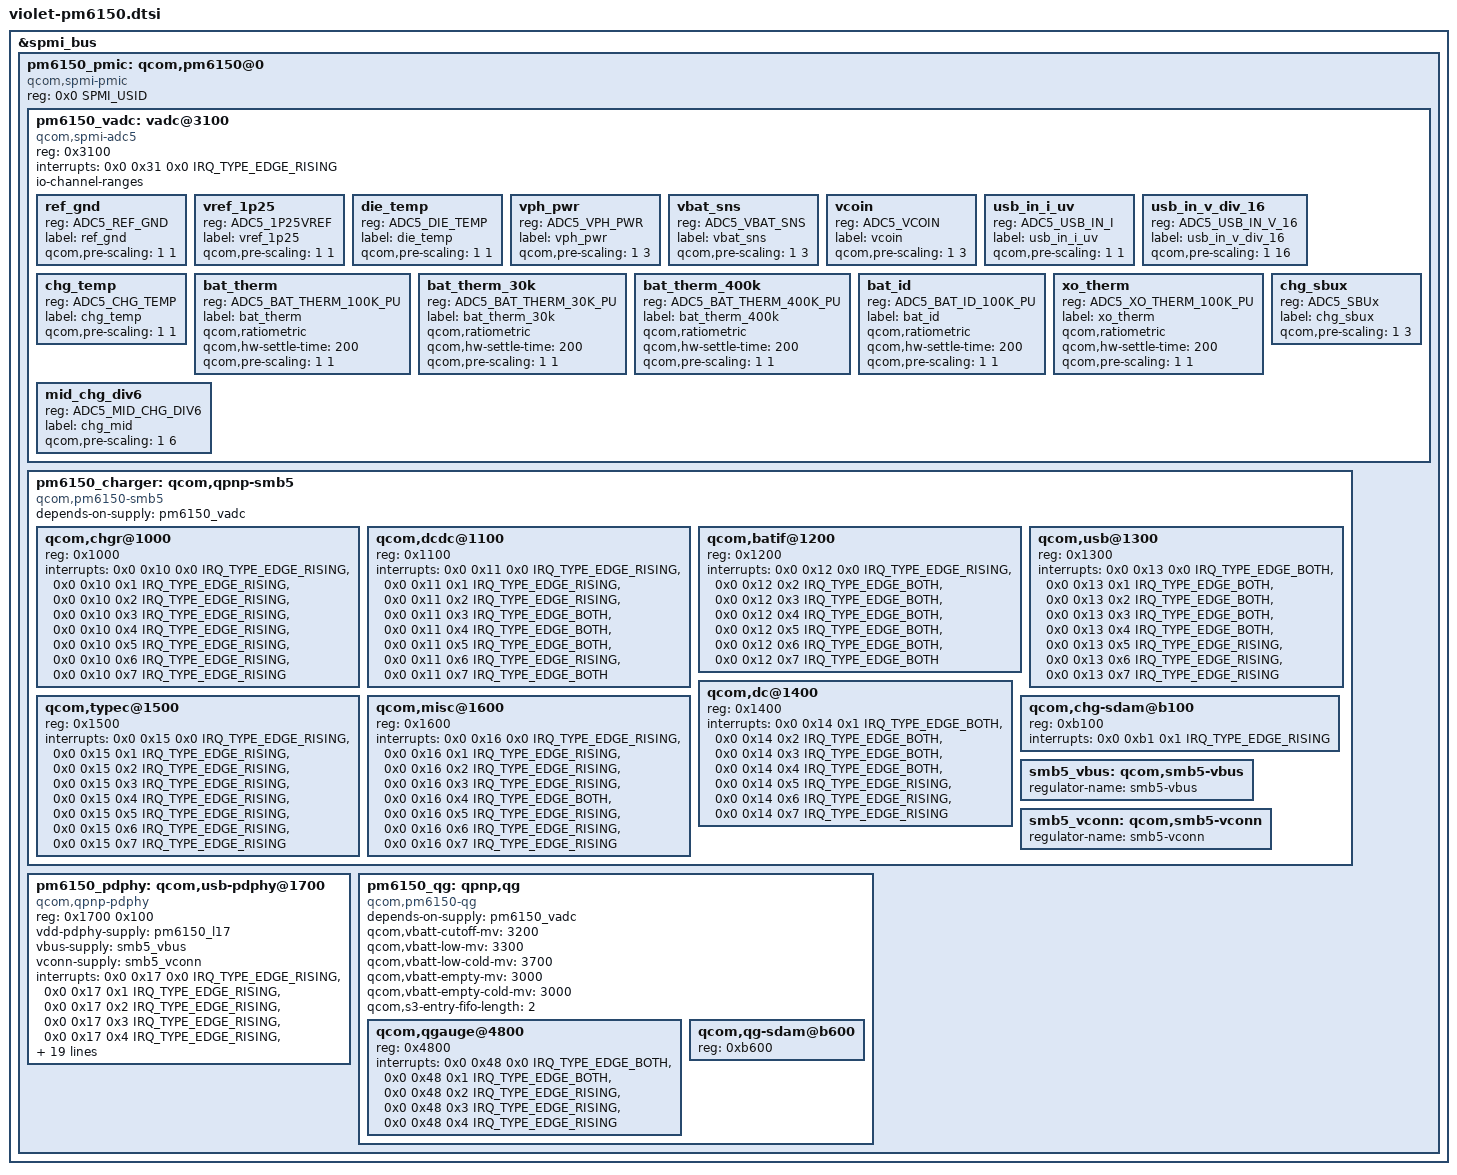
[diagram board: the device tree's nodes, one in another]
// SPDX-License-Identifier: GPL-2.0-only
/*
 * DEBUG (bring-up): pm6150 (SID 0) for the 6.1 charger/gauge drivers. Generated
 * from the 4.14 pm6150.dtsi with the 6.1 binding (single-cell reg, IIO
 * channels, pm6150-smb5 / pm6150-qg compatibles).
 */
#include <dt-bindings/spmi/spmi.h>
#include <dt-bindings/interrupt-controller/irq.h>
#include <dt-bindings/iio/qcom,spmi-vadc.h>
#include <dt-bindings/iio/qti_power_supply_iio.h>

&spmi_bus {
	pm6150_pmic: qcom,pm6150@0 {
		compatible = "qcom,spmi-pmic";
		reg = <0x0 SPMI_USID>;
		#address-cells = <1>;
		#size-cells = <0>;

		pm6150_vadc: vadc@3100 {
			compatible = "qcom,spmi-adc5";
			reg = <0x3100>;
			#address-cells = <1>;
			#size-cells = <0>;
			interrupts = <0x0 0x31 0x0 IRQ_TYPE_EDGE_RISING>;
			interrupt-names = "eoc-int-en-set";
			#io-channel-cells = <1>;
			io-channel-ranges;

			/* Channel nodes */
			ref_gnd {
				reg = <ADC5_REF_GND>;
				label = "ref_gnd";
				qcom,pre-scaling = <1 1>;
			};

			vref_1p25 {
				reg = <ADC5_1P25VREF>;
				label = "vref_1p25";
				qcom,pre-scaling = <1 1>;
			};

			die_temp {
				reg = <ADC5_DIE_TEMP>;
				label = "die_temp";
				qcom,pre-scaling = <1 1>;
			};

			vph_pwr {
				reg = <ADC5_VPH_PWR>;
				label = "vph_pwr";
				qcom,pre-scaling = <1 3>;
			};

			vbat_sns {
				reg = <ADC5_VBAT_SNS>;
				label = "vbat_sns";
				qcom,pre-scaling = <1 3>;
			};

			vcoin {
				reg = <ADC5_VCOIN>;
				label = "vcoin";
				qcom,pre-scaling = <1 3>;
			};

			usb_in_i_uv {
				reg = <ADC5_USB_IN_I>;
				label = "usb_in_i_uv";
				qcom,pre-scaling = <1 1>;
			};

			usb_in_v_div_16 {
				reg = <ADC5_USB_IN_V_16>;
				label = "usb_in_v_div_16";
				qcom,pre-scaling = <1 16>;
			};

			chg_temp {
				reg = <ADC5_CHG_TEMP>;
				label = "chg_temp";
				qcom,pre-scaling = <1 1>;
			};

			bat_therm {
				reg = <ADC5_BAT_THERM_100K_PU>;
				label = "bat_therm";
				qcom,ratiometric;
				qcom,hw-settle-time = <200>;
				qcom,pre-scaling = <1 1>;
			};

			bat_therm_30k {
				reg = <ADC5_BAT_THERM_30K_PU>;
				label = "bat_therm_30k";
				qcom,ratiometric;
				qcom,hw-settle-time = <200>;
				qcom,pre-scaling = <1 1>;
			};

			bat_therm_400k {
				reg = <ADC5_BAT_THERM_400K_PU>;
				label = "bat_therm_400k";
				qcom,ratiometric;
				qcom,hw-settle-time = <200>;
				qcom,pre-scaling = <1 1>;
			};

			bat_id {
				reg = <ADC5_BAT_ID_100K_PU>;
				label = "bat_id";
				qcom,ratiometric;
				qcom,hw-settle-time = <200>;
				qcom,pre-scaling = <1 1>;
			};

			xo_therm {
				reg = <ADC5_XO_THERM_100K_PU>;
				label = "xo_therm";
				qcom,ratiometric;
				qcom,hw-settle-time = <200>;
				qcom,pre-scaling = <1 1>;
			};

			chg_sbux {
				reg = <ADC5_SBUx>;
				label = "chg_sbux";
				qcom,pre-scaling = <1 3>;
			};

			mid_chg_div6 {
				reg = <ADC5_MID_CHG_DIV6>;
				label = "chg_mid";
				qcom,pre-scaling = <1 6>;
			};



		};

		pm6150_charger: qcom,qpnp-smb5 {
			compatible = "qcom,pm6150-smb5";
			depends-on-supply = <&pm6150_vadc>;
			#address-cells = <1>;
			#size-cells = <0>;
			#cooling-cells = <2>;


			qcom,chgr@1000 {
				reg = <0x1000>;
				interrupts =
					<0x0 0x10 0x0 IRQ_TYPE_EDGE_RISING>,
					<0x0 0x10 0x1 IRQ_TYPE_EDGE_RISING>,
					<0x0 0x10 0x2 IRQ_TYPE_EDGE_RISING>,
					<0x0 0x10 0x3 IRQ_TYPE_EDGE_RISING>,
					<0x0 0x10 0x4 IRQ_TYPE_EDGE_RISING>,
					<0x0 0x10 0x5 IRQ_TYPE_EDGE_RISING>,
					<0x0 0x10 0x6 IRQ_TYPE_EDGE_RISING>,
					<0x0 0x10 0x7 IRQ_TYPE_EDGE_RISING>;

				interrupt-names = "chgr-error",
						  "chg-state-change",
						  "step-chg-state-change",
						  "step-chg-soc-update-fail",
						  "step-chg-soc-update-req",
						  "fg-fvcal-qualified",
						  "vph-alarm",
						  "vph-drop-prechg";
			};

			qcom,dcdc@1100 {
				reg = <0x1100>;
				interrupts =
					<0x0 0x11 0x0 IRQ_TYPE_EDGE_RISING>,
					<0x0 0x11 0x1 IRQ_TYPE_EDGE_RISING>,
					<0x0 0x11 0x2 IRQ_TYPE_EDGE_RISING>,
					<0x0 0x11 0x3 IRQ_TYPE_EDGE_BOTH>,
					<0x0 0x11 0x4 IRQ_TYPE_EDGE_BOTH>,
					<0x0 0x11 0x5 IRQ_TYPE_EDGE_BOTH>,
					<0x0 0x11 0x6 IRQ_TYPE_EDGE_RISING>,
					<0x0 0x11 0x7 IRQ_TYPE_EDGE_BOTH>;

				interrupt-names = "otg-fail",
						  "otg-oc-disable-sw",
						  "otg-oc-hiccup",
						  "bsm-active",
						  "high-duty-cycle",
						  "input-current-limiting",
						  "concurrent-mode-disable",
						  "switcher-power-ok";
			};

			qcom,batif@1200 {
				reg = <0x1200>;
				interrupts =
					<0x0 0x12 0x0 IRQ_TYPE_EDGE_RISING>,
					<0x0 0x12 0x2 IRQ_TYPE_EDGE_BOTH>,
					<0x0 0x12 0x3 IRQ_TYPE_EDGE_BOTH>,
					<0x0 0x12 0x4 IRQ_TYPE_EDGE_BOTH>,
					<0x0 0x12 0x5 IRQ_TYPE_EDGE_BOTH>,
					<0x0 0x12 0x6 IRQ_TYPE_EDGE_BOTH>,
					<0x0 0x12 0x7 IRQ_TYPE_EDGE_BOTH>;

				interrupt-names = "bat-temp",
						  "bat-ov",
						  "bat-low",
						  "bat-therm-or-id-missing",
						  "bat-terminal-missing",
						  "buck-oc",
						  "vph-ov";
			};

			qcom,usb@1300 {
				reg = <0x1300>;
				interrupts =
					<0x0 0x13 0x0 IRQ_TYPE_EDGE_BOTH>,
					<0x0 0x13 0x1 IRQ_TYPE_EDGE_BOTH>,
					<0x0 0x13 0x2 IRQ_TYPE_EDGE_BOTH>,
					<0x0 0x13 0x3 IRQ_TYPE_EDGE_BOTH>,
					<0x0 0x13 0x4 IRQ_TYPE_EDGE_BOTH>,
					<0x0 0x13 0x5 IRQ_TYPE_EDGE_RISING>,
					<0x0 0x13 0x6 IRQ_TYPE_EDGE_RISING>,
					<0x0 0x13 0x7 IRQ_TYPE_EDGE_RISING>;

				interrupt-names = "usbin-collapse",
						  "usbin-vashdn",
						  "usbin-uv",
						  "usbin-ov",
						  "usbin-plugin",
						  "usbin-revi-change",
						  "usbin-src-change",
						  "usbin-icl-change";
			};

			qcom,dc@1400 {
				reg = <0x1400>;
				interrupts =
					<0x0 0x14 0x1 IRQ_TYPE_EDGE_BOTH>,
					<0x0 0x14 0x2 IRQ_TYPE_EDGE_BOTH>,
					<0x0 0x14 0x3 IRQ_TYPE_EDGE_BOTH>,
					<0x0 0x14 0x4 IRQ_TYPE_EDGE_BOTH>,
					<0x0 0x14 0x5 IRQ_TYPE_EDGE_RISING>,
					<0x0 0x14 0x6 IRQ_TYPE_EDGE_RISING>,
					<0x0 0x14 0x7 IRQ_TYPE_EDGE_RISING>;

				interrupt-names = "dcin-vashdn",
						  "dcin-uv",
						  "dcin-ov",
						  "dcin-plugin",
						  "dcin-revi",
						  "dcin-pon",
						  "dcin-en";
			};

			qcom,typec@1500 {
				reg = <0x1500>;
				interrupts =
					<0x0 0x15 0x0 IRQ_TYPE_EDGE_RISING>,
					<0x0 0x15 0x1 IRQ_TYPE_EDGE_RISING>,
					<0x0 0x15 0x2 IRQ_TYPE_EDGE_RISING>,
					<0x0 0x15 0x3 IRQ_TYPE_EDGE_RISING>,
					<0x0 0x15 0x4 IRQ_TYPE_EDGE_RISING>,
					<0x0 0x15 0x5 IRQ_TYPE_EDGE_RISING>,
					<0x0 0x15 0x6 IRQ_TYPE_EDGE_RISING>,
					<0x0 0x15 0x7 IRQ_TYPE_EDGE_RISING>;

				interrupt-names = "typec-or-rid-detect-change",
						  "typec-vpd-detect",
						  "typec-cc-state-change",
						  "typec-vconn-oc",
						  "typec-vbus-change",
						  "typec-attach-detach",
						  "typec-legacy-cable-detect",
						  "typec-try-snk-src-detect";
			};

			qcom,misc@1600 {
				reg = <0x1600>;
				interrupts =
					<0x0 0x16 0x0 IRQ_TYPE_EDGE_RISING>,
					<0x0 0x16 0x1 IRQ_TYPE_EDGE_RISING>,
					<0x0 0x16 0x2 IRQ_TYPE_EDGE_RISING>,
					<0x0 0x16 0x3 IRQ_TYPE_EDGE_RISING>,
					<0x0 0x16 0x4 IRQ_TYPE_EDGE_BOTH>,
					<0x0 0x16 0x5 IRQ_TYPE_EDGE_RISING>,
					<0x0 0x16 0x6 IRQ_TYPE_EDGE_RISING>,
					<0x0 0x16 0x7 IRQ_TYPE_EDGE_RISING>;

				interrupt-names = "wdog-snarl",
						  "wdog-bark",
						  "aicl-fail",
						  "aicl-done",
						  "smb-en",
						  "imp-trigger",
						  "temp-change",
						  "temp-change-smb";
			};

			qcom,chg-sdam@b100 {
				reg = <0xb100>;
				interrupts =
					<0x0 0xb1 0x1 IRQ_TYPE_EDGE_RISING>;
				interrupt-names = "sdam-sts";
			};

			smb5_vbus: qcom,smb5-vbus {
				regulator-name = "smb5-vbus";
			};

			smb5_vconn: qcom,smb5-vconn {
				regulator-name = "smb5-vconn";
			};
		};

		/*
		 * USB-PD PHY + policy engine. On a Type-C port the policy
		 * engine, not smb5, reports VBUS/role to dwc3 through its
		 * extcon (smb5 only drives its own extcon for micro-USB).
		 * Same node as 4.14 pm6150.dtsi, with the 6.1 IIO links to
		 * the charger (as blair-cdp does for pm7250b).
		 */
		pm6150_pdphy: qcom,usb-pdphy@1700 {
			compatible = "qcom,qpnp-pdphy";
			reg = <0x1700 0x100>;
			vdd-pdphy-supply = <&pm6150_l17>;
			vbus-supply = <&smb5_vbus>;
			vconn-supply = <&smb5_vconn>;
			interrupts = <0x0 0x17 0x0 IRQ_TYPE_EDGE_RISING>,
				     <0x0 0x17 0x1 IRQ_TYPE_EDGE_RISING>,
				     <0x0 0x17 0x2 IRQ_TYPE_EDGE_RISING>,
				     <0x0 0x17 0x3 IRQ_TYPE_EDGE_RISING>,
				     <0x0 0x17 0x4 IRQ_TYPE_EDGE_RISING>,
				     <0x0 0x17 0x5 IRQ_TYPE_EDGE_RISING>,
				     <0x0 0x17 0x6 IRQ_TYPE_EDGE_RISING>,
				     <0x0 0x17 0x7 IRQ_TYPE_EDGE_RISING>;
			interrupt-names = "sig-tx",
					  "sig-rx",
					  "msg-tx",
					  "msg-rx",
					  "msg-tx-failed",
					  "msg-tx-discarded",
					  "msg-rx-discarded",
					  "fr-swap";

			qcom,default-sink-caps = <5000 3000>, /* 5V @ 3A */
						 <9000 3000>, /* 9V @ 3A */
						 <12000 2250>; /* 12V @ 2.25A */

			#io-channel-cells = <1>;
			io-channels = <&pm6150_charger PSY_IIO_PD_ACTIVE>,
				      <&pm6150_charger PSY_IIO_TYPEC_CC_ORIENTATION>,
				      <&pm6150_charger PSY_IIO_CONNECTOR_TYPE>,
				      <&pm6150_charger PSY_IIO_TYPEC_POWER_ROLE>,
				      <&pm6150_charger PSY_IIO_PD_USB_SUSPEND_SUPPORTED>,
				      <&pm6150_charger PSY_IIO_TYPEC_SRC_RP>,
				      <&pm6150_charger PSY_IIO_PD_IN_HARD_RESET>,
				      <&pm6150_charger PSY_IIO_PD_CURRENT_MAX>,
				      <&pm6150_charger PSY_IIO_PR_SWAP>,
				      <&pm6150_charger PSY_IIO_PD_VOLTAGE_MIN>,
				      <&pm6150_charger PSY_IIO_PD_VOLTAGE_MAX>,
				      <&pm6150_charger PSY_IIO_USB_REAL_TYPE>,
				      <&pm6150_charger PSY_IIO_TYPEC_MODE>,
				      <&pm6150_charger PSY_IIO_PE_START>;
			io-channel-names = "pd_active",
					   "typec_cc_orientation",
					   "connector_type",
					   "typec_power_role",
					   "pd_usb_suspend_supported",
					   "typec_src_rp",
					   "pd_in_hard_reset",
					   "pr_current_max",
					   "pr_swap",
					   "pd_voltage_min",
					   "pd_voltage_max",
					   "real_type",
					   "typec_mode",
					   "pe_start";
		};

		pm6150_qg: qpnp,qg {
			compatible = "qcom,pm6150-qg";
			depends-on-supply = <&pm6150_vadc>;
			#address-cells = <1>;
			#size-cells = <0>;

			qcom,vbatt-cutoff-mv = <3200>;
			qcom,vbatt-low-mv = <3300>;
			qcom,vbatt-low-cold-mv = <3700>;
			qcom,vbatt-empty-mv = <3000>;
			qcom,vbatt-empty-cold-mv = <3000>;
			qcom,s3-entry-fifo-length = <2>;


			qcom,qgauge@4800 {
				status = "okay";
				reg = <0x4800>;
				interrupts =
					<0x0 0x48 0x0 IRQ_TYPE_EDGE_BOTH>,
					<0x0 0x48 0x1 IRQ_TYPE_EDGE_BOTH>,
					<0x0 0x48 0x2 IRQ_TYPE_EDGE_RISING>,
					<0x0 0x48 0x3 IRQ_TYPE_EDGE_RISING>,
					<0x0 0x48 0x4 IRQ_TYPE_EDGE_RISING>;
				interrupt-names = "qg-batt-missing",
						  "qg-vbat-low",
						  "qg-vbat-empty",
						  "qg-fifo-done",
						  "qg-good-ocv";
			};

			qcom,qg-sdam@b600 {
				status = "okay";
				reg = <0xb600>;
			};
		};
	};
};
